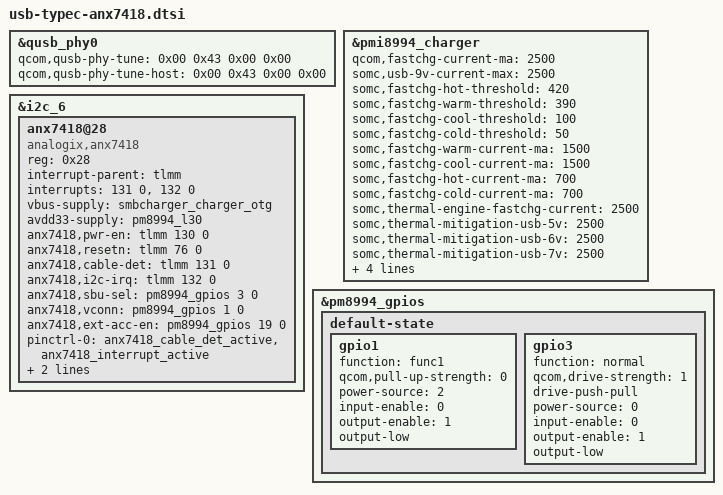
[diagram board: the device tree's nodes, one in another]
/* Copyright (c) 2015, The Linux Foundation. All rights reserved.
 *
 * This program is free software; you can redistribute it and/or modify
 * it under the terms of the GNU General Public License version 2 and
 * only version 2 as published by the Free Software Foundation.
 *
 * This program is distributed in the hope that it will be useful,
 * but WITHOUT ANY WARRANTY; without even the implied warranty of
 * MERCHANTABILITY or FITNESS FOR A PARTICULAR PURPOSE.  See the
 * GNU General Public License for more details.
 */

/* From usb dtsi - same tuning */
&qusb_phy0 {
	qcom,qusb-phy-tune = <0x00 0x43 0x00 0x00>;
	qcom,qusb-phy-tune-host = <0x00 0x43 0x00 0x00>;
};

&pmi8994_charger {
	qcom,fastchg-current-ma = <2500>;
	somc,usb-9v-current-max = <2500>;
	somc,fastchg-hot-threshold = <420>;
	somc,fastchg-warm-threshold = <390>;
	somc,fastchg-cool-threshold = <100>;
	somc,fastchg-cold-threshold = <50>;
	somc,fastchg-warm-current-ma = <1500>;
	somc,fastchg-cool-current-ma = <1500>;
	somc,fastchg-hot-current-ma  = <700>;
	somc,fastchg-cold-current-ma = <700>;
	somc,thermal-engine-fastchg-current = <2500>;
	somc,thermal-mitigation-usb-5v = <2500>;
	somc,thermal-mitigation-usb-6v = <2500>;
	somc,thermal-mitigation-usb-7v = <2500>;
	somc,thermal-mitigation-usb-8v = <2500>;
	somc,thermal-mitigation-usb-9v = <2500>;
	somc,typec-current-max = <2500>;
    somc,adj-charge-limit-enabled;
};

&i2c_6 {
	anx7418@28 {
		compatible = "analogix,anx7418";
		reg = <0x28>;

		interrupt-parent = <&tlmm>;
		interrupts = <131 0>, <132 0>;

		vbus-supply = <&smbcharger_charger_otg>;
		avdd33-supply = <&pm8994_l30>;

		anx7418,pwr-en = <&tlmm 130 0>;
		anx7418,resetn = <&tlmm 76 0>;
		anx7418,cable-det = <&tlmm 131 0>;
		anx7418,i2c-irq = <&tlmm 132 0>;
		anx7418,sbu-sel = <&pm8994_gpios 3 0>;
		anx7418,vconn = <&pm8994_gpios 1 0>;
		anx7418,ext-acc-en = <&pm8994_gpios 19 0>;

		status = "ok";

		pinctrl-names = "default", "sleep";
		pinctrl-0	= <&anx7418_cable_det_active &anx7418_interrupt_active>;
		pinctrl-1	= <&anx7418_cable_det_sleep &anx7418_interrupt_sleep>;
	};
};

&pm8994_gpios {
	default-state {
	gpio1 {
			function = "func1";
			/delete-property/ bias-disable;
			/delete-property/ bias-pull-down;
			/delete-property/ qcom,pull-up-strength;
			qcom,pull-up-strength = <0>;
			power-source = <2>;
			input-enable = <0>;
			output-enable = <1>;
			/delete-property/ output-low;
			/delete-property/ output-high;
			output-low;
			/delete-property/ bias-high-impedance;
			status = "okay";
		};

	gpio3 {
			function = "normal";
			qcom,drive-strength = <1>;
			drive-push-pull;
			power-source = <0>;
			input-enable = <0>;
			output-enable = <1>;
			/delete-property/ output-low;
			/delete-property/ output-high;
			output-low;
			/delete-property/ bias-high-impedance;
			status = "okay";
		};
	};
};
